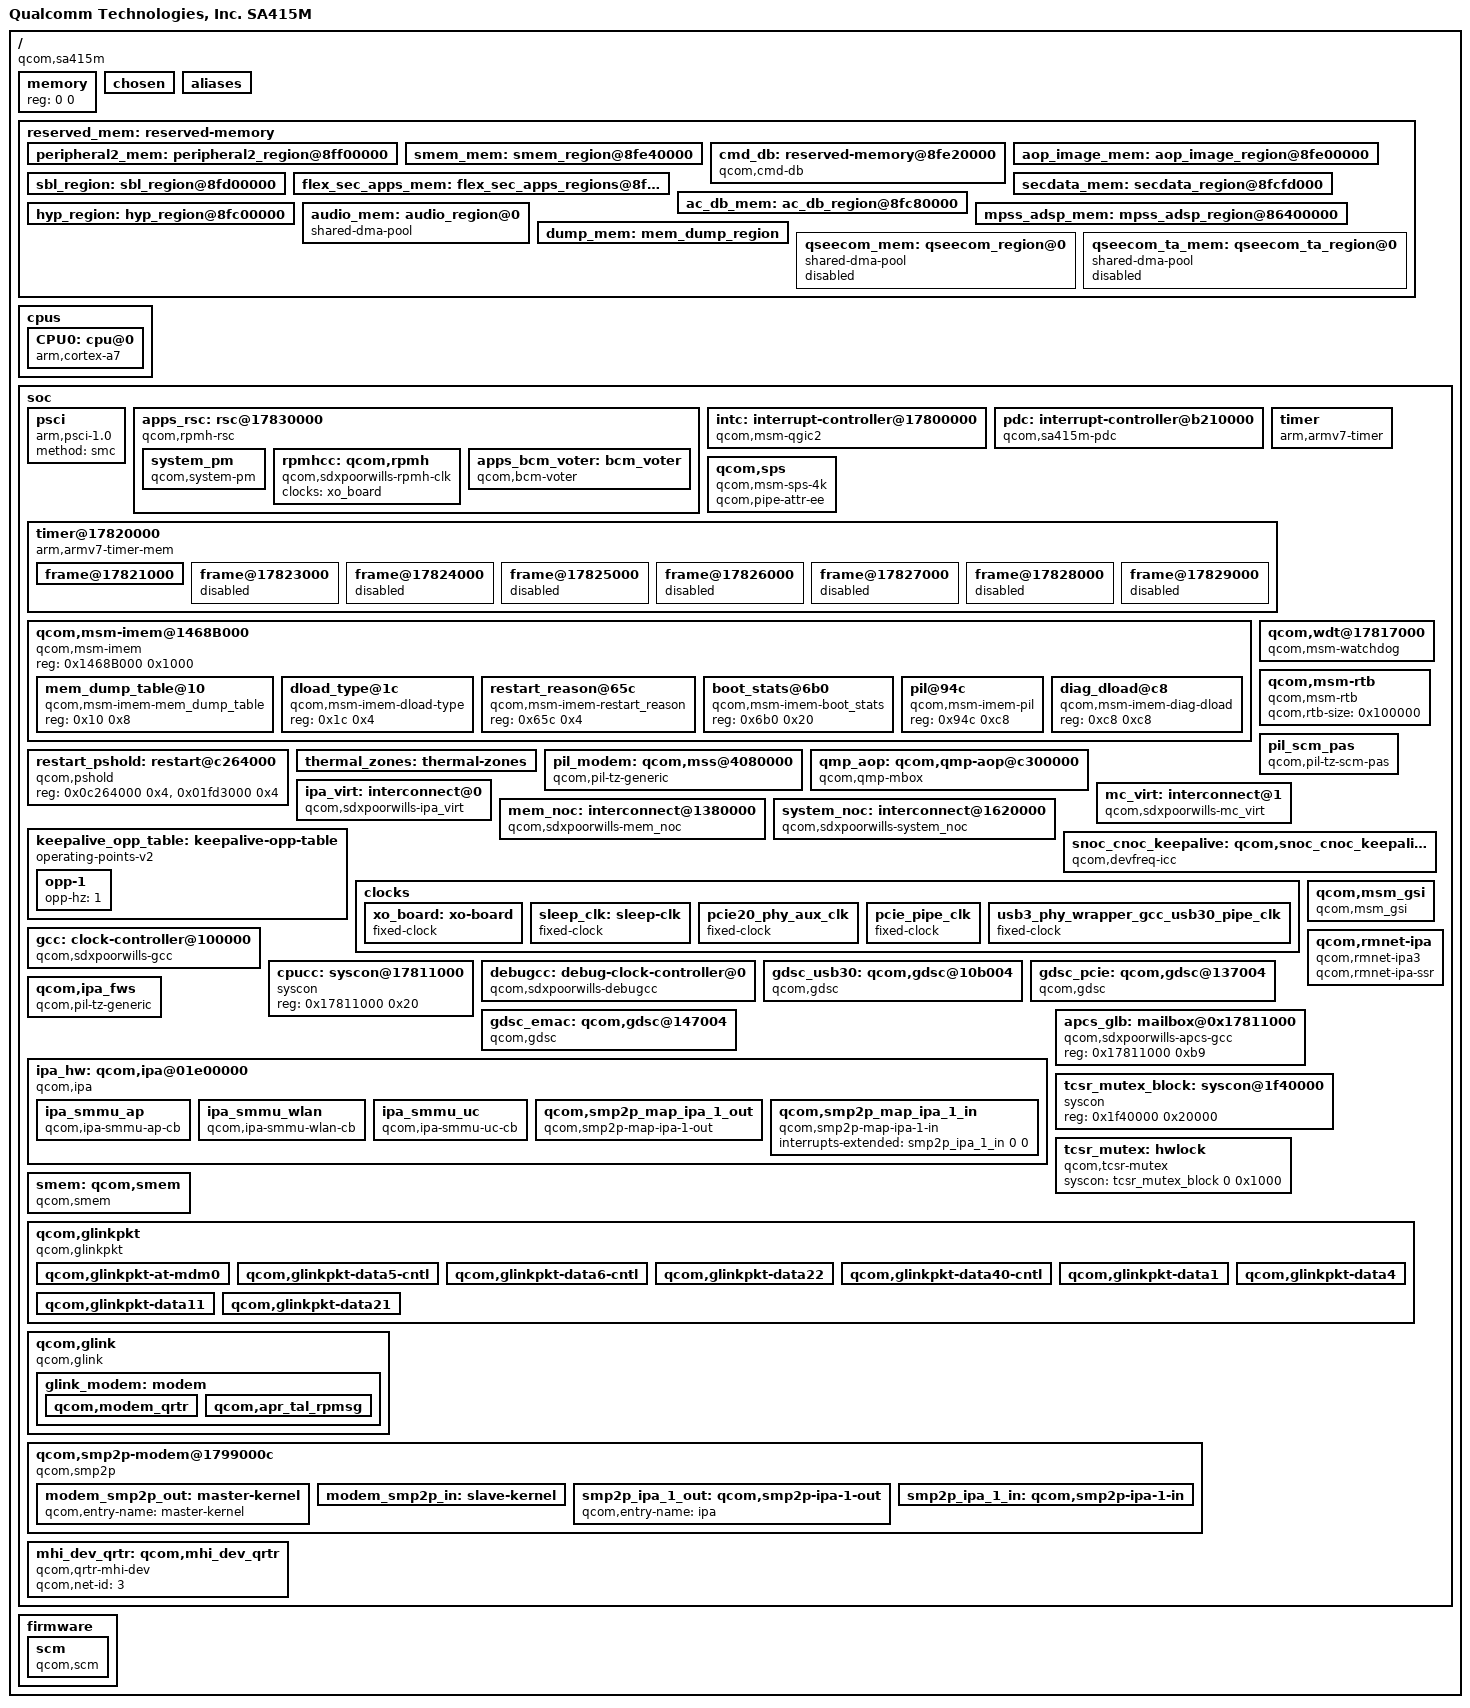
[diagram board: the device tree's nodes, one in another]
#include <dt-bindings/clock/qcom,rpmh.h>
#include <dt-bindings/clock/qcom,gcc-sdxpoorwills.h>
#include <dt-bindings/interconnect/qcom,sdxpoorwills.h>
#include <dt-bindings/interrupt-controller/arm-gic.h>
#include <dt-bindings/soc/qcom,rpmh-rsc.h>

/ {
	#address-cells = <1>;
	#size-cells = <1>;
	model = "Qualcomm Technologies, Inc. SA415M";
	compatible = "qcom,sa415m";
	qcom,msm-id = <334 0x0>, <335 0x0>, <408 0x0>;

	interrupt-parent = <&intc>;

	memory { device_type = "memory"; reg = <0 0>; };

	chosen: chosen { };

	aliases {
	};

	reserved_mem: reserved-memory {
		#address-cells = <1>;
		#size-cells = <1>;
		ranges;

		peripheral2_mem: peripheral2_region@8ff00000 {
			no-map;
			reg = <0x8ff00000 0xd00000>;
			label = "peripheral2_mem";
		};

		smem_mem: smem_region@8fe40000 {
			no-map;
			reg = <0x8fe40000 0xc0000>;
			label = "smem_mem";
		};

		cmd_db: reserved-memory@8fe20000 {
			compatible = "qcom,cmd-db";
			no-map;
			reg = <0x8fe20000 0x20000>;
		};

		aop_image_mem: aop_image_region@8fe00000 {
			no-map;
			reg = <0x8fe00000 0x20000>;
		};

		sbl_region: sbl_region@8fd00000 {
			no-map;
			reg = <0x8fd00000 0x100000>;
			label = "sbl_mem";
		};

		flex_sec_apps_mem: flex_sec_apps_regions@8fcfe000 {
			no-map;
			reg = <0x8fcfe000 0x2000>;
		};

		secdata_mem: secdata_region@8fcfd000 {
			no-map;
			reg = <0x8fcfd000 0x1000>;
			label = "secdata_mem";
		};

		ac_db_mem: ac_db_region@8fc80000 {
			no-map;
			reg = <0x8fc80000 0x40000>;
			label = "ac_db_mem";
		};

		hyp_region: hyp_region@8fc00000 {
			no-map;
			reg = <0x8fc00000 0x80000>;
			label = "hyp_mem";
		};

		mpss_adsp_mem: mpss_adsp_region@86400000 {
			no-map;
			reg = <0x86400000 0x9300000>;
			label = "mpss_adsp_mem";
		};

		audio_mem: audio_region@0 {
			compatible = "shared-dma-pool";
			reusable;
			size = <0x400000>;
		};

		dump_mem: mem_dump_region {
			reusable;
			size = <0x400000>;
		};

		qseecom_mem: qseecom_region@0 {
			compatible = "shared-dma-pool";
			reusable;
			alignment = <0x400000>;
			size = <0x800000>;
			status = "disabled";
		};

		qseecom_ta_mem: qseecom_ta_region@0 {
			compatible = "shared-dma-pool";
			reusable;
			alignment = <0x400000>;
			size = <0x400000>;
			status = "disabled";
		};
	};

	cpus {
		#size-cells = <0>;
		#address-cells = <1>;

		CPU0: cpu@0 {
			device_type = "cpu";
			compatible = "arm,cortex-a7";
			enable-method = "psci";
			cpu-idle-states = <&A7_SPC &A7_PC &CX_MIN>;
			reg = <0x0>;
			#cooling-cells = <2>;
		};
	};

	soc: soc { };

	firmware: firmware {};
};

&soc {
	#address-cells = <1>;
	#size-cells = <1>;
	ranges;

	psci {
		compatible = "arm,psci-1.0";
		method = "smc";
	};

	apps_rsc: rsc@17830000 {
		label = "apps_rsc";
		compatible = "qcom,rpmh-rsc";
		reg = <0x17830000 0x10000>,
		      <0x17840000 0x10000>;
		reg-names = "drv-0", "drv-1";
		interrupts = <GIC_SPI 16 IRQ_TYPE_LEVEL_HIGH>,
			     <GIC_SPI 17 IRQ_TYPE_LEVEL_HIGH>;
		qcom,tcs-offset = <0xd00>;
		qcom,drv-id = <1>;
		qcom,tcs-config = <ACTIVE_TCS  2>,
				  <SLEEP_TCS   2>,
				  <WAKE_TCS    2>,
				  <CONTROL_TCS 1>;

		system_pm {
			compatible = "qcom,system-pm";
		};

		rpmhcc: qcom,rpmh {
			compatible = "qcom,sdxpoorwills-rpmh-clk";
			clocks = <&xo_board>;
			clock-names = "xo";
			#clock-cells = <1>;
		};

		apps_bcm_voter: bcm_voter {
			compatible = "qcom,bcm-voter";
		};
	};

	intc: interrupt-controller@17800000 {
		compatible = "qcom,msm-qgic2";
		interrupt-controller;
		interrupt-parent = <&intc>;
		#interrupt-cells = <3>;
		reg = <0x17800000 0x1000>,
		      <0x17802000 0x1000>;
	};

	pdc: interrupt-controller@b210000 {
		compatible = "qcom,sa415m-pdc";
		reg = <0xb210000 0x30000>,
		      <0xb204900 0x700>;
		reg-names = "base", "mux-base";
		qcom,pdc-ranges = <0 147 52>;
		qcom,pdc-mux-ranges = <20 20 0>, <21 27 1>, <22 30 2>,
				      <23 31 3>, <24 40 4>, <25 45 5>,
				      <26 54 6>;
		#interrupt-cells = <2>;
		interrupt-parent = <&intc>;
		interrupt-controller;
	};

	timer {
		compatible = "arm,armv7-timer";
		interrupts = <1 13 0xf08>,
			<1 12 0xf08>,
			<1 10 0xf08>,
			<1 11 0xf08>;
		clock-frequency = <19200000>;
	};

	qcom,sps {
		compatible = "qcom,msm-sps-4k";
		qcom,pipe-attr-ee;
	};

	timer@17820000 {
		#address-cells = <1>;
		#size-cells = <1>;
		ranges;
		compatible = "arm,armv7-timer-mem";
		reg = <0x17820000 0x1000>;
		clock-frequency = <19200000>;

		frame@17821000 {
			frame-number = <0>;
			interrupts = <0 7 0x4>,
				     <0 6 0x4>;
			reg = <0x17821000 0x1000>,
			      <0x17822000 0x1000>;
		};

		frame@17823000 {
			frame-number = <1>;
			interrupts = <0 8 0x4>;
			reg = <0x17823000 0x1000>;
			status = "disabled";
		};

		frame@17824000 {
			frame-number = <2>;
			interrupts = <0 9 0x4>;
			reg = <0x17824000 0x1000>;
			status = "disabled";
		};

		frame@17825000 {
			frame-number = <3>;
			interrupts = <0 10 0x4>;
			reg = <0x17825000 0x1000>;
			status = "disabled";
		};

		frame@17826000 {
			frame-number = <4>;
			interrupts = <0 11 0x4>;
			reg = <0x17826000 0x1000>;
			status = "disabled";
		};

		frame@17827000 {
			frame-number = <5>;
			interrupts = <0 12 0x4>;
			reg = <0x17827000 0x1000>;
			status = "disabled";
		};

		frame@17828000 {
			frame-number = <6>;
			interrupts = <0 13 0x4>;
			reg = <0x17828000 0x1000>;
			status = "disabled";
		};

		frame@17829000 {
			frame-number = <7>;
			interrupts = <0 14 0x4>;
			reg = <0x17829000 0x1000>;
			status = "disabled";
		};
	};

	qcom,msm-imem@1468B000 {
		compatible = "qcom,msm-imem";
		reg = <0x1468B000 0x1000>; /* Address and size of IMEM */
		ranges = <0x0 0x1468B000 0x1000>;
		#address-cells = <1>;
		#size-cells = <1>;

		mem_dump_table@10 {
			compatible = "qcom,msm-imem-mem_dump_table";
			reg = <0x10 0x8>;
		};

		dload_type@1c {
			compatible = "qcom,msm-imem-dload-type";
			reg = <0x1c 0x4>;
		};

		restart_reason@65c {
			compatible = "qcom,msm-imem-restart_reason";
			reg = <0x65c 0x4>;
		};

		boot_stats@6b0 {
			compatible = "qcom,msm-imem-boot_stats";
			reg = <0x6b0 0x20>;
		};

		pil@94c {
			compatible = "qcom,msm-imem-pil";
			reg = <0x94c 0xc8>;
		};

		diag_dload@c8 {
			compatible = "qcom,msm-imem-diag-dload";
			reg = <0xc8 0xc8>;
		};
	};

	qcom,wdt@17817000 {
		compatible = "qcom,msm-watchdog";
		reg = <0x17817000 0x1000>;
		reg-names = "wdt-base";
		interrupts = <1 3 0>, <1 2 0>;
		qcom,bark-time = <11000>;
		qcom,pet-time = <9360>;
		qcom,wakeup-enable;
	};

	restart_pshold: restart@c264000 {
		compatible = "qcom,pshold";
		reg = <0x0c264000 0x4>,
			<0x01fd3000 0x4>;
		reg-names = "pshold-base", "tcsr-boot-misc-detect";
	};

	qcom,msm-rtb {
		compatible = "qcom,msm-rtb";
		qcom,rtb-size = <0x100000>;
	};

	thermal_zones: thermal-zones {
	};

	pil_modem: qcom,mss@4080000 {
		compatible = "qcom,pil-tz-generic";
		reg = <0x4080000 0x100>;

		clocks = <&rpmhcc RPMH_CXO_CLK>;
		clock-names = "xo";
		qcom,proxy-clock-names = "xo";

		vdd_cx-supply = <&VDD_CX_LEVEL>;
		vdd_mss-supply = <&pmxpoorwills_s1_level>;
		qcom,proxy-reg-names = "vdd_cx", "vdd_mss";

		qcom,firmware-name = "modem";
		memory-region = <&mpss_adsp_mem>;
		qcom,pas-id = <4>;
		qcom,smem-id = <421>;
		qcom,sysmon-id = <0>;
		qcom,ssctl-instance-id = <0x22>;

		interrupts-extended = <&intc 0 250 1>,
			<&modem_smp2p_in 0 0>,
			<&modem_smp2p_in 2 0>,
			<&modem_smp2p_in 1 0>,
			<&modem_smp2p_in 3 0>,
			<&modem_smp2p_in 7 0>;

		interrupt-names = "qcom,wdog",
			"qcom,err-fatal",
			"qcom,proxy-unvote",
			"qcom,err-ready",
			"qcom,stop-ack",
			"qcom,shutdown-ack";

		qcom,smem-states = <&modem_smp2p_out 0>;
		qcom,smem-state-names = "qcom,force-stop";

		status = "ok";
	};

	pil_scm_pas {
		compatible = "qcom,pil-tz-scm-pas";
		interconnects = <&system_noc MASTER_CRYPTO
			&mc_virt SLAVE_EBI1>;
	};

	qmp_aop: qcom,qmp-aop@c300000 {
		compatible = "qcom,qmp-mbox";
		reg = <0xc300000 0x400>, <0x17811008 0x4>;
		reg-names = "msgram", "irq-reg-base";
		qcom,irq-mask = <0x1>;
		interrupts = <GIC_SPI 221 IRQ_TYPE_EDGE_RISING>;

		label = "aop";
		qcom,early-boot;
		priority = <0>;
		mbox-desc-offset = <0x0>;
		#mbox-cells = <1>;
	};

	ipa_virt: interconnect@0 {
		compatible = "qcom,sdxpoorwills-ipa_virt";
		#interconnect-cells = <1>;
		qcom,bcm-voter-names = "hlos";
		qcom,bcm-voters = <&apps_bcm_voter>;
	};

	mc_virt: interconnect@1 {
		compatible = "qcom,sdxpoorwills-mc_virt";
		#interconnect-cells = <1>;
		qcom,bcm-voter-names = "hlos";
		qcom,bcm-voters = <&apps_bcm_voter>;
	};

	mem_noc: interconnect@1380000 {
		compatible = "qcom,sdxpoorwills-mem_noc";
		reg = <0x01380000 0x27200>;
		#interconnect-cells = <1>;
		qcom,bcm-voter-names = "hlos";
		qcom,bcm-voters = <&apps_bcm_voter>;
	};

	system_noc: interconnect@1620000 {
		compatible = "qcom,sdxpoorwills-system_noc";
		reg = <0x1620000 0x2B080>;
		#interconnect-cells = <1>;
		qcom,bcm-voter-names = "hlos";
		qcom,bcm-voters = <&apps_bcm_voter>;
	};

	keepalive_opp_table: keepalive-opp-table {
		compatible = "operating-points-v2";
		opp-1 {
			opp-hz = /bits/ 64 < 1 >;
		};
	};

	snoc_cnoc_keepalive: qcom,snoc_cnoc_keepalive {
		compatible = "qcom,devfreq-icc";
		governor = "powersave";
		interconnects = <&system_noc MASTER_QDSS_BAM &system_noc SLAVE_AOP>;
		operating-points-v2 = <&keepalive_opp_table>;
		qcom,active-only;
		status = "ok";
	};

	clocks {
		xo_board: xo-board {
			compatible = "fixed-clock";
			clock-frequency = <38400000>;
			clock-output-names = "xo_board";
			#clock-cells = <0>;
		};

		sleep_clk: sleep-clk {
			compatible = "fixed-clock";
			clock-frequency = <32000>;
			clock-output-names = "sleep_clk";
			#clock-cells = <0>;
		};

		pcie20_phy_aux_clk: pcie20_phy_aux_clk {
			compatible = "fixed-clock";
			clock-frequency = <1000>;
			clock-output-names = "pcie20_phy_aux_clk";
			#clock-cells = <0>;
		};

		pcie_pipe_clk: pcie_pipe_clk {
			compatible = "fixed-clock";
			clock-frequency = <1000>;
			clock-output-names = "pcie_pipe_clk";
			#clock-cells = <0>;
		};

		usb3_phy_wrapper_gcc_usb30_pipe_clk: usb3_phy_wrapper_gcc_usb30_pipe_clk {
			compatible = "fixed-clock";
			clock-frequency = <1000>;
			clock-output-names = "usb3_phy_wrapper_gcc_usb30_pipe_clk";
			#clock-cells = <0>;
		};
	};

	gcc: clock-controller@100000 {
		compatible = "qcom,sdxpoorwills-gcc", "syscon";
		reg = <0x100000 0x1f0000>;
		reg-names = "cc_base";
		clocks = <&rpmhcc RPMH_CXO_CLK>, <&rpmhcc RPMH_CXO_CLK_A>,
			<&sleep_clk>, <&pcie20_phy_aux_clk>, <&pcie_pipe_clk>,
			<&usb3_phy_wrapper_gcc_usb30_pipe_clk>;
		clock-names = "bi_tcxo", "bi_tcxo_ao", "sleep_clk",
			"pcie20_phy_aux_clk", "pcie_pipe_clk",
			"usb3_phy_wrapper_gcc_usb30_pipe_clk";
		vdd_cx-supply = <&VDD_CX_LEVEL>;
		vdd_cx_ao-supply = <&VDD_CX_LEVEL_AO>;
		#clock-cells = <1>;
		#reset-cells = <1>;
	};

	cpucc: syscon@17811000 {
		compatible = "syscon";
		reg = <0x17811000 0x20>;
	};

	debugcc: debug-clock-controller@0 {
		compatible = "qcom,sdxpoorwills-debugcc";
		qcom,gcc = <&gcc>;
		qcom,apsscc = <&cpucc>;
		clock-names = "xo_clk_src";
		clocks = <&rpmhcc RPMH_CXO_CLK>;
		#clock-cells = <1>;
	};

	/* GDSCs in Global CC */
	gdsc_usb30: qcom,gdsc@10b004 {
		compatible = "qcom,gdsc";
		regulator-name = "gdsc_usb30";
		reg = <0x0010b004 0x4>;
	};

	gdsc_pcie: qcom,gdsc@137004 {
		compatible = "qcom,gdsc";
		regulator-name = "gdsc_pcie";
		reg = <0x00137004 0x4>;
	};

	gdsc_emac: qcom,gdsc@147004 {
		compatible = "qcom,gdsc";
		regulator-name = "gdsc_emac";
		reg = <0x00147004 0x4>;
	};

	qcom,msm_gsi {
		compatible = "qcom,msm_gsi";
	};

	qcom,rmnet-ipa {
		compatible = "qcom,rmnet-ipa3";
		qcom,rmnet-ipa-ssr;
	};

	qcom,ipa_fws {
		compatible = "qcom,pil-tz-generic";
		qcom,pas-id = <0xf>;
		qcom,firmware-name = "ipa_fws";
		qcom,pil-force-shutdown;
	};

	ipa_hw: qcom,ipa@01e00000 {
		compatible = "qcom,ipa";
		reg = <0x1e00000 0x34000>,
			<0x1e04000 0x28000>;
		reg-names = "ipa-base", "gsi-base";
		interrupts =
			<0 241 0>,
			<0 47 0>;
		interrupt-names = "ipa-irq", "gsi-irq";
		qcom,ipa-hw-ver = <14>; /* IPA core version = IPAv4.0 */
		qcom,ipa-hw-mode = <0>;
		qcom,ee = <0>;
		qcom,use-ipa-tethering-bridge;
		qcom,mhi-event-ring-id-limits = <9 11>; /* start and end */
		qcom,modem-cfg-emb-pipe-flt;
		qcom,use-ipa-pm;
		qcom,use-xbl-boot;
		qcom,wlan-ce-db-over-pcie;
		qcom,arm-smmu;
		qcom,smmu-fast-map;
		qcom,bandwidth-vote-for-ipa;
		qcom,msm-bus,name = "ipa";
		qcom,msm-bus,num-cases = <5>;
		qcom,msm-bus,num-paths = <5>;
		qcom,wan-aggr-time-limit = <2>;
		qcom,lan-aggr-time-limit = <2>;
		qcom,rndis-aggr-time-limit = <2>;
		qcom,ipa-config-is-auto;
		qcom,max_num_smmu_cb = <3>;
		qcom,interconnect,num-cases = <5>;
		qcom,interconnect,num-paths = <5>;

		interconnects = <&system_noc MASTER_IPA &system_noc SLAVE_SNOC_MEM_NOC_GC>,
				<&mem_noc MASTER_SNOC_GC_MEM_NOC &mc_virt SLAVE_EBI1>,
				<&system_noc MASTER_IPA &system_noc SLAVE_IMEM>,
				<&mem_noc MASTER_APPSS_PROC &system_noc SLAVE_IPA_CFG>,
				<&ipa_virt MASTER_IPA_CORE &ipa_virt SLAVE_IPA_CORE>;
		interconnect-names = "ipa_to_memnoc", "ipa_to_ebi1", "ipa_to_imem", "appsproc_to_ipacfg", "ipacore_to_ipacore";

		/* No vote */
		qcom,no-vote =
		<0 0 0 0 0 0 0 0 0 0>;

		/* SVS2 */
		qcom,svs2 =
		<116000 480000 116000 1800000 60000 600000 17900 179000 0 120>;

		/* SVS */
		qcom,svs =
		<225000 720000 225000 3060000 80000 800000 19900 199000 0 250>;

		/* NOMINAL */
		qcom,nominal =
		<375000 1560000 375000 5184000 160000 1600000 39900 399000 0 440>;

		/* TURBO */
		qcom,turbo =
		<960000 1920000 2592000 5184000 960000 1920000 266000 531000 0 500>;

		qcom,throughput-threshold = <310 600 1000>;
		qcom,scaling-exceptions = <>;

		/* ipa tz unlock registers */
		qcom,ipa-tz-unlock-reg =
				<0x4043583c 0x1000>; /* 32-bit reg addr and size*/

		ipa_smmu_ap: ipa_smmu_ap {
			compatible = "qcom,ipa-smmu-ap-cb";
			iommus = <&apps_smmu 0x5E0 0x0>;
			qcom,iommu-dma-addr-pool = <0x20000000 0x40000000>;
			qcom,additional-mapping =
				/* modem tables in IMEM */
				<0x14686000 0x14686000 0x3000>;
			qcom,ipa-q6-smem-size = <16384>;
			qcom,iommu-dma = "fastmap";
		};

		ipa_smmu_wlan: ipa_smmu_wlan {
			compatible = "qcom,ipa-smmu-wlan-cb";
			iommus = <&apps_smmu 0x5E1 0x0>;
			qcom,additional-mapping =
				/* ipa-uc ram */
				<0x1E60000 0x1E60000 0xA000>;
		};

		ipa_smmu_uc: ipa_smmu_uc {
			compatible = "qcom,ipa-smmu-uc-cb";
			iommus = <&apps_smmu 0x5E2 0x0>;
			qcom,iommu-dma-addr-pool = <0x40000000 0x20000000>;
		};

		/* smp2p information */
		qcom,smp2p_map_ipa_1_out {
			compatible = "qcom,smp2p-map-ipa-1-out";
			qcom,smem-states = <&smp2p_ipa_1_out 0>;
			qcom,smem-state-names = "ipa-smp2p-out";
		};

		qcom,smp2p_map_ipa_1_in {
			compatible = "qcom,smp2p-map-ipa-1-in";
			interrupts-extended = <&smp2p_ipa_1_in 0 0>;
			interrupt-names = "ipa-smp2p-in";
		};
	};

	apcs_glb: mailbox@0x17811000 {
		compatible = "qcom,sdxpoorwills-apcs-gcc";
		reg = <0x17811000 0xb9>;
		#mbox-cells = <1>;
	};

	tcsr_mutex_block: syscon@1f40000 {
		compatible = "syscon";
		reg = <0x1f40000 0x20000>;
	};

	tcsr_mutex: hwlock {
		compatible = "qcom,tcsr-mutex";
		syscon = <&tcsr_mutex_block 0 0x1000>;
		#hwlock-cells = <1>;
	};

	smem: qcom,smem {
		compatible = "qcom,smem";
		memory-region = <&smem_mem>;
		hwlocks = <&tcsr_mutex 3>;
	};

	qcom,glinkpkt {
		compatible = "qcom,glinkpkt";

		qcom,glinkpkt-at-mdm0 {
			qcom,glinkpkt-edge = "mpss";
			qcom,glinkpkt-ch-name = "DS";
			qcom,glinkpkt-dev-name = "at_mdm0";
		};

		qcom,glinkpkt-data5-cntl {
			qcom,glinkpkt-edge = "mpss";
			qcom,glinkpkt-ch-name = "DATA5_CNTL";
			qcom,glinkpkt-dev-name = "smdcntl0";
		};

		qcom,glinkpkt-data6-cntl {
			qcom,glinkpkt-edge = "mpss";
			qcom,glinkpkt-ch-name = "DATA6_CNTL";
			qcom,glinkpkt-dev-name = "smdcntl1";
		};

		qcom,glinkpkt-data22 {
			qcom,glinkpkt-edge = "mpss";
			qcom,glinkpkt-ch-name = "DATA22";
			qcom,glinkpkt-dev-name = "smd22";
		};

		qcom,glinkpkt-data40-cntl {
			qcom,glinkpkt-edge = "mpss";
			qcom,glinkpkt-ch-name = "DATA40_CNTL";
			qcom,glinkpkt-dev-name = "smdcntl8";
		};

		qcom,glinkpkt-data1 {
			qcom,glinkpkt-edge = "mpss";
			qcom,glinkpkt-ch-name = "DATA1";
			qcom,glinkpkt-dev-name = "smd7";
		};

		qcom,glinkpkt-data4 {
			qcom,glinkpkt-edge = "mpss";
			qcom,glinkpkt-ch-name = "DATA4";
			qcom,glinkpkt-dev-name = "smd8";
		};

		qcom,glinkpkt-data11 {
			qcom,glinkpkt-edge = "mpss";
			qcom,glinkpkt-ch-name = "DATA11";
			qcom,glinkpkt-dev-name = "smd11";
		};

		qcom,glinkpkt-data21 {
			qcom,glinkpkt-edge = "mpss";
			qcom,glinkpkt-ch-name = "DATA21";
			qcom,glinkpkt-dev-name = "smd21";
		};

	};

	qcom,glink {
		compatible = "qcom,glink";
		#address-cells = <1>;
		#size-cells = <1>;
		ranges;

		glink_modem: modem {
			qcom,remote-pid = <1>;
			transport = "smem";
			mboxes = <&apcs_glb 15>;
			mbox-names = "mpss_smem";
			interrupts = <GIC_SPI 114 IRQ_TYPE_EDGE_RISING>;

			label = "modem";
			qcom,glink-label = "mpss";

			qcom,modem_qrtr {
				qcom,glink-channels = "IPCRTR";
				qcom,intents = <0x800  5
						0x2000 3
						0x4400 2>;
			};

			qcom,apr_tal_rpmsg {
				qcom,glink-channels = "apr_audio_svc";
				qcom,intents = <0x200 20>;
			};
		};
	};

	qcom,smp2p-modem@1799000c {
		compatible = "qcom,smp2p";
		qcom,smem = <435>, <428>;
		interrupts = <GIC_SPI 113 IRQ_TYPE_EDGE_RISING>;
		mboxes = <&apcs_glb 14>;
		qcom,local-pid = <0>;
		qcom,remote-pid = <1>;

		modem_smp2p_out: master-kernel {
			qcom,entry-name = "master-kernel";
			#qcom,smem-state-cells = <1>;
		};

		modem_smp2p_in: slave-kernel {
			qcom,entry-name = "slave-kernel";
			interrupt-controller;
			#interrupt-cells = <2>;
		};

		smp2p_ipa_1_out: qcom,smp2p-ipa-1-out {
			qcom,entry-name = "ipa";
			#qcom,smem-state-cells = <1>;
		};

		/* ipa - inbound entry from mss */
		smp2p_ipa_1_in: qcom,smp2p-ipa-1-in {
			qcom,entry-name = "ipa";
			interrupt-controller;
			#interrupt-cells = <2>;
		};
	};

	mhi_dev_qrtr: qcom,mhi_dev_qrtr {
		compatible = "qcom,qrtr-mhi-dev";
		qcom,net-id = <3>;
	};

};

#include "sdxpoorwills-regulator.dtsi"
#include "sa415m-pinctrl.dtsi"
#include "sa415m-ion.dtsi"
#include "sa415m-pm.dtsi"
#include "sdxpoorwills-thermal.dtsi"
#include "msm-arm-smmu-sa415m.dtsi"

&firmware {
	scm {
		compatible = "qcom,scm";
	};
};
